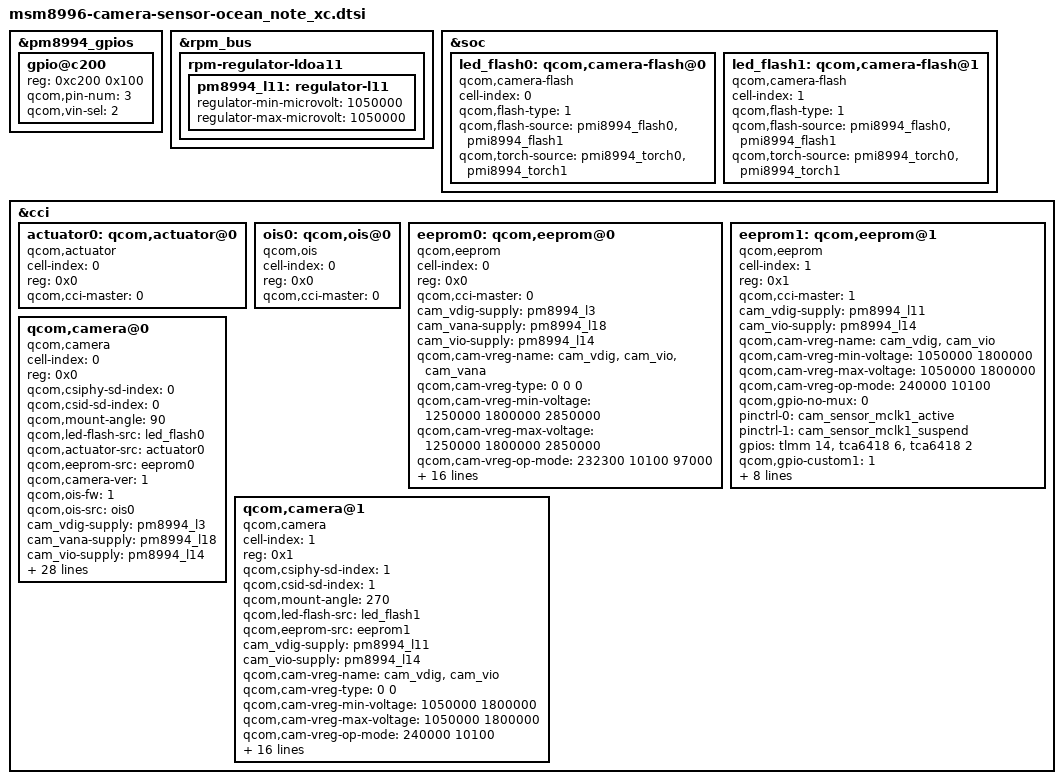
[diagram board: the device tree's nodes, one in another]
&pm8994_gpios {
    gpio@c200 {
                reg = <0xc200 0x100>;
                qcom,pin-num = <3>;
                qcom,vin-sel = <2>;  /* VIN2 */
                status = "ok";
            };
};

&rpm_bus {
 rpm-regulator-ldoa11 {
  status = "okay";
  pm8994_l11: regulator-l11 {
   regulator-min-microvolt = <1050000>;
   regulator-max-microvolt = <1050000>;
   status = "okay";
  };
 };
};

&soc {
        led_flash0: qcom,camera-flash@0 {
                cell-index = <0>;
                compatible = "qcom,camera-flash";
                qcom,flash-type = <1>;
                qcom,flash-source = <&pmi8994_flash0 &pmi8994_flash1>;
                qcom,torch-source = <&pmi8994_torch0 &pmi8994_torch1>;
        };
        led_flash1: qcom,camera-flash@1 {
                cell-index = <1>;
                compatible = "qcom,camera-flash";
                qcom,flash-type = <1>;
                qcom,flash-source = <&pmi8994_flash0 &pmi8994_flash1>;
                qcom,torch-source = <&pmi8994_torch0 &pmi8994_torch1>;
        };
};

&cci {

    actuator0: qcom,actuator@0 {
                cell-index = <0>;
                reg = <0x0>;
                compatible = "qcom,actuator";
                qcom,cci-master = <0>;
    };

    ois0: qcom,ois@0 {
                cell-index = <0>;
                reg = <0x0>;
                compatible = "qcom,ois";
                qcom,cci-master = <0>;
    };


    eeprom0: qcom,eeprom@0 {
    cell-index = <0>;
    reg = <0x0>;
    compatible = "qcom,eeprom";
    qcom,cci-master = <0>;
    cam_vdig-supply = <&pm8994_l3>;//212mA
    cam_vana-supply =<&pm8994_l18>;//91mA
    cam_vio-supply = <&pm8994_l14>;//7mA
    qcom,cam-vreg-name = "cam_vdig", "cam_vio", "cam_vana";
    qcom,cam-vreg-type = <0 0 0>;
    qcom,cam-vreg-min-voltage = <1250000 1800000 2850000>;
    qcom,cam-vreg-max-voltage = <1250000 1800000 2850000>;
    qcom,cam-vreg-op-mode = <232300 10100 97000>;//uA
    qcom,gpio-no-mux = <0>;
    pinctrl-names = "cam_default", "cam_suspend";
    pinctrl-0 = <&cam_sensor_mclk0_active>;
    pinctrl-1 = <&cam_sensor_mclk0_suspend>;
    gpios = <&tlmm 13 0>,
    <&tca6418 1 0>,
    <&tca6418 8 0>,
    <&tca6418 5 0>,
    <&tca6418 7 0>;
    qcom,gpio-reset = <1>;
    qcom,gpio-vaf = <2>;
    qcom,gpio-custom1 = <3>;
    qcom,gpio-vana = <4>;
    qcom,gpio-req-tbl-num = <0 1 2 3 4>;
    qcom,gpio-req-tbl-flags = <1 0 0 0 0>;
    qcom,gpio-req-tbl-label = "CAMIF_MCLK",
    "CAM_RST",
    "VCM_2V85",
    "CAM1_DRV_A2V8_EN",
    "CAM1_A2V8";
    clocks = <&clock_mmss clk_mclk0_clk_src>,
    <&clock_mmss clk_camss_mclk0_clk>;
    clock-names = "cam_src_clk", "cam_clk";
    qcom,clock-rates = <24000000 0>;
    };

    eeprom1: qcom,eeprom@1 {
        cell-index = <1>;
        reg = <0x1>;
        compatible = "qcom,eeprom";
        qcom,cci-master = <1>;
        cam_vdig-supply = <&pm8994_l11>;
        cam_vio-supply = <&pm8994_l14>;
        qcom,cam-vreg-name = "cam_vdig", "cam_vio";
        qcom,cam-vreg-min-voltage = <1050000 1800000>;
        qcom,cam-vreg-max-voltage = <1050000 1800000>;
        qcom,cam-vreg-op-mode = <240000 10100>;
        qcom,gpio-no-mux = <0>;
        pinctrl-names = "cam_default", "cam_suspend";
        pinctrl-0 = <&cam_sensor_mclk1_active>;
        pinctrl-1 = <&cam_sensor_mclk1_suspend>;
		gpios = <&tlmm 14 0>,
			    <&tca6418 6 0>,
			    <&tca6418 2 0>;
		qcom,gpio-custom1 = <1>;
		qcom,gpio-custom2 = <2>;
		qcom,gpio-req-tbl-num = <0 1 2>;
		qcom,gpio-req-tbl-flags = <1 0 0>;
		qcom,gpio-req-tbl-label = "CAMIF_MCLK",
					              "CAM2_A2V85",
					              "FCAM_PWDN";
        clocks = <&clock_mmss clk_mclk1_clk_src>,
                <&clock_mmss clk_camss_mclk1_clk>;
        clock-names = "cam_src_clk", "cam_clk";
        qcom,clock-rates = <24000000 0>;
    };

     qcom,camera@0 {
                cell-index = <0>;
                compatible = "qcom,camera";
                reg = <0x0>;
                //qcom,slave-id = <0x34 0x3044 0x0032>;//
                qcom,csiphy-sd-index = <0>;
                qcom,csid-sd-index = <0>;
                qcom,mount-angle = <90>;
                qcom,led-flash-src = <&led_flash0>;
                qcom,actuator-src = <&actuator0>;
                qcom,eeprom-src = <&eeprom0>;
                //qcom,sensor-name = "imx377_htc";
                qcom,camera-ver = <1>;
		qcom,ois-fw = <1>;
                qcom,ois-src = <&ois0>;
                cam_vdig-supply = <&pm8994_l3>;//212mA
                cam_vana-supply =<&pm8994_l18>;//91mA
                cam_vio-supply = <&pm8994_l14>;//7mA
                flash_rw = <&tca6418 11 0>;
                qcom,cam-vreg-name = "cam_vdig", "cam_vio", "cam_vana";
                qcom,cam-vreg-type = <0 0 0>;
                qcom,cam-vreg-min-voltage = <1250000 1800000 2850000>;
                qcom,cam-vreg-max-voltage = <1250000 1800000 2850000>;
                qcom,cam-vreg-op-mode = <232300 10100 97000>;//uA
                qcom,gpio-no-mux = <0>;
                pinctrl-names = "cam_default", "cam_suspend";
                pinctrl-0 = <&cam_sensor_mclk0_active>;
                pinctrl-1 = <&cam_sensor_mclk0_suspend>;
                gpios = <&tlmm 13 0>,
                        <&tca6418 1 0>,
                        <&tca6418 8 0>,
                        <&tca6418 5 0>,
                        <&tca6418 7 0>;
                qcom,gpio-reset = <1>;
                qcom,gpio-vaf = <2>;
                qcom,gpio-custom1 = <3>;
                qcom,gpio-vana = <4>;
                qcom,gpio-req-tbl-num = <0 1 2 3 4>;
                qcom,gpio-req-tbl-flags = <1 0 0 0 0>;
                qcom,gpio-req-tbl-label = "CAMIF_MCLK",
                                        "CAM_RST",
                                        "VCM_2V85",
                                        "CAM1_DRV_A2V8_EN",
                                        "CAM1_A2V8";
                //qcom,csi-lane-assign = <0x4320>;
                //qcom,csi-lane-mask = <0x1F>;
                qcom,sensor-position = <0>;
                qcom,sensor-mode = <0>;
                qcom,cci-master = <0>;
                status = "ok";
                clocks = <&clock_mmss clk_mclk0_clk_src>,
                                <&clock_mmss clk_camss_mclk0_clk>;
                clock-names = "cam_src_clk", "cam_clk";
                qcom,clock-rates = <24000000 0>;
      };

    qcom,camera@1 {
		cell-index = <1>;
		compatible = "qcom,camera";
		reg = <0x1>;
		qcom,csiphy-sd-index = <1>;
		qcom,csid-sd-index = <1>;
		qcom,mount-angle = <270>;
		qcom,led-flash-src = <&led_flash1>;
		qcom,eeprom-src = <&eeprom1>;
		cam_vdig-supply = <&pm8994_l11>;
		cam_vio-supply = <&pm8994_l14>;
		qcom,cam-vreg-name = "cam_vdig", "cam_vio";
		qcom,cam-vreg-type = <0 0>;
		qcom,cam-vreg-min-voltage = <1050000 1800000>;
		qcom,cam-vreg-max-voltage = <1050000 1800000>;
		qcom,cam-vreg-op-mode = <240000 10100>;
		qcom,gpio-no-mux = <0>;
		pinctrl-names = "cam_default", "cam_suspend";
		pinctrl-0 = <&cam_sensor_mclk1_active>;
		pinctrl-1 = <&cam_sensor_mclk1_suspend>;
		gpios = <&tlmm 14 0>,
			    <&tca6418 6 0>,
			    <&tca6418 2 0>;
		qcom,gpio-custom1 = <1>;
		qcom,gpio-custom2 = <2>;
		qcom,gpio-req-tbl-num = <0 1 2>;
		qcom,gpio-req-tbl-flags = <1 0 0>;
		qcom,gpio-req-tbl-label = "CAMIF_MCLK",
					              "CAM2_A2V85",
					              "FCAM_PWDN";
		qcom,sensor-position = <1>;
		qcom,sensor-mode = <1>;
		qcom,cci-master = <1>;
		status = "ok";
		clocks = <&clock_mmss clk_mclk1_clk_src>,
				 <&clock_mmss clk_camss_mclk1_clk>;
		clock-names = "cam_src_clk", "cam_clk";
		qcom,clock-rates = <24000000 0>;
	};
};

